# va108xx register map
Vendor: VORAGO TECHNOLOGIES; Series: M0; File version: 1.2-IAR
ARM 32-bit Cortex-M0 Microcontroller based device, CPU clock up to 50MHz
CPU: CM0 r0p0, little endian, no MPU, no FPU, 2 interrupt priority bits
Registers are 32-bit, read-write, reset 0x0 unless marked. A register's access mark holds for its fields unless they carry their own. Offsets are from the block's base; lines under a group give offsets from that group; [hi:lo] are bit positions; {n}, {i} and the like mark numbered series; 'fields as' and 'values as' point back to an identical list; <NAME> marks a mode.

## Memory map
0x40000000 SYSCONFIG size 0x1000 — System Configuration Peripheral
0x40001000 IRQSEL size 0x1000 — Interrupt Selector Peripheral
0x40002000 IOCONFIG size 0x1000 — IO Pin Configuration Peripheral
0x40003000 UTILITY size 0x1000 — Utility Peripheral
0x40020000 TIM0 size 0x1000 — Timer/Counter Peripheral
{0x40020000+0x1000*n} TIM{n} size 0x1000 (n=1..23)
0x40040000 UARTA size 0x1000 — UART Peripheral
0x40041000 UARTB size 0x1000
0x40050000 SPIA size 0x1000 — SPI Peripheral
0x40051000 SPIB size 0x1000
0x40052000 SPIC size 0x1000
0x40060000 I2CA size 0x1000 — I2C Peripheral
0x40061000 I2CB size 0x1000
0x50000000 PORTA size 0x1000 — GPIO Peripheral
0x50001000 PORTB size 0x1000

## Interrupts
{n} OC{n} (IRQSEL) (n=0..31)

## SYSCONFIG — System Configuration Peripheral
Base 0x40000000
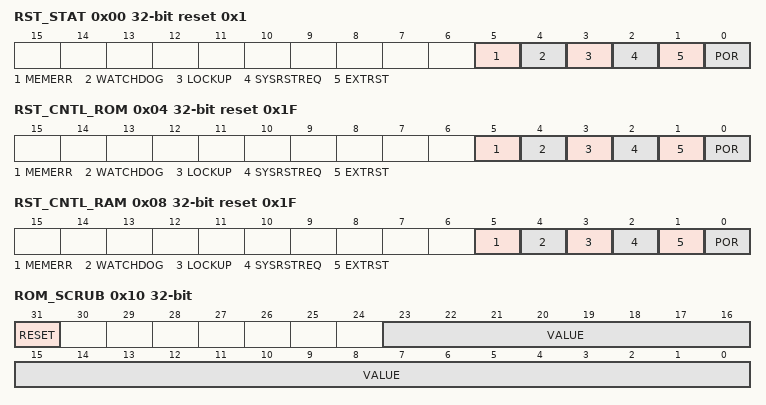
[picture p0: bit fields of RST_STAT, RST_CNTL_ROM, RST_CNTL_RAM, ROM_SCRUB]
0x00 RST_STAT reset 0x1 — System Reset Status
  [5] MEMERR — Memory Error Reset Status
  [4] WATCHDOG — WATCHDOG Reset Status
  [3] LOCKUP — LOCKUP Reset Status
  [2] SYSRSTREQ — SYSRESETREQ Reset Status
  [1] EXTRST — External Reset Status
  [0] POR — Power On Reset Status
0x04 RST_CNTL_ROM reset 0x1F — ROM Reset Control
  fields as RST_STAT
0x08 RST_CNTL_RAM reset 0x1F — RAM Reset Control
  fields as RST_STAT
0x0C ROM_PROT reset 0x1 — ROM Protection Configuration
  [0] WREN — ROM Write Enable Bit
0x10 ROM_SCRUB — ROM Scrub Period Configuration
  [31] RESET wo write-1-clears — Reset Counter
  [23:0] VALUE — Counter divide value
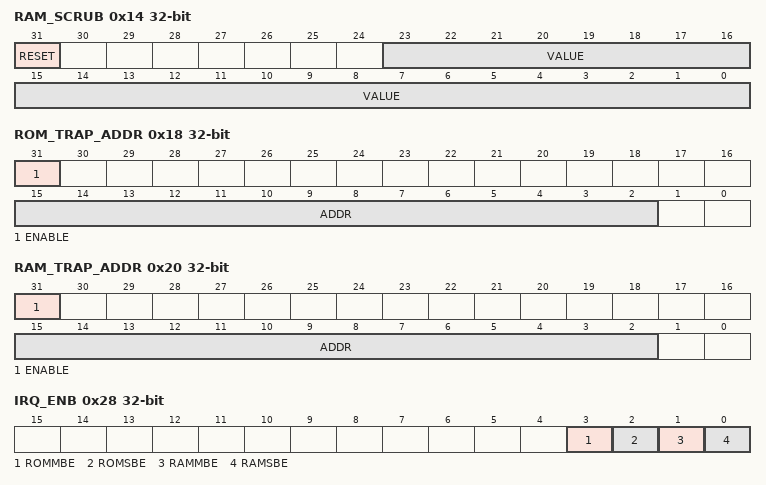
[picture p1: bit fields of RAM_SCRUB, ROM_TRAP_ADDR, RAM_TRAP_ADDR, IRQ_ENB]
0x14 RAM_SCRUB — RAM Scrub Period Configuration
  fields as ROM_SCRUB
0x18 ROM_TRAP_ADDR — ROM Trap Address
  [31] ENABLE — Trap Enable Bit
  [15:2] ADDR — Trap Address Match Bits
0x1C ROM_TRAP_SYND — ROM Trap Syndrome
  [19:0] SYND — Trap Syndrom Bits
0x20 RAM_TRAP_ADDR — RAM Trap Address
  fields as ROM_TRAP_ADDR
0x24 RAM_TRAP_SYND — RAM Trap Syndrome
  [19:0] SYND — Trap Syndrom Bits
0x28 IRQ_ENB — Enable EDAC Error Interrupt Register
  [3] ROMMBE — ROM Multi Bit Interrupt
  [2] ROMSBE — ROM Single Bit Interrupt
  [1] RAMMBE — RAM Multi Bit Interrupt
  [0] RAMSBE — RAM Single Bit Interrupt
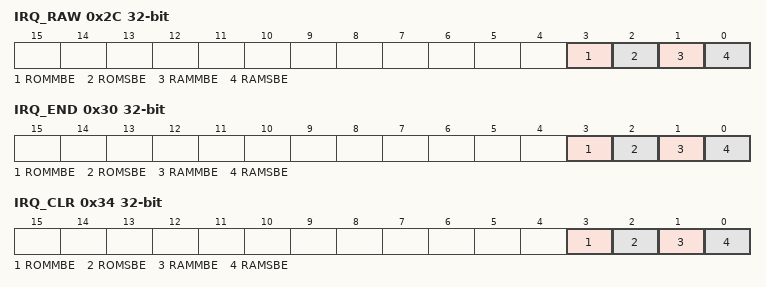
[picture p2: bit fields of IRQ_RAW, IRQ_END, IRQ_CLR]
0x2C IRQ_RAW ro — Raw EDAC Error Interrupt Status
  fields as IRQ_ENB
0x30 IRQ_END ro — Enabled EDAC Error Interrupt Status
  fields as IRQ_ENB
0x34 IRQ_CLR wo write-1-clears — Clear EDAC Error Interrupt Status
  fields as IRQ_ENB
0x38 RAM_SBE — Count of RAM EDAC Single Bit Errors
0x3C RAM_MBE — Count of RAM EDAC Multi Bit Errors
0x40 ROM_SBE — Count of ROM EDAC Single Bit Errors
0x44 ROM_MBE — Count of ROM EDAC Multi Bit Errors
0x48 IOCONFIG_CLKDIV0 ro — IO Configuration Clock Divider Register
{0x48+4i} IOCONFIG_CLKDIV{i} (i=1..7) — IO Configuration Clock Divider Register
0x68 ROM_RETRIES ro — ROM BOOT Retry count
0x6C REFRESH_CONFIG — Register Refresh Control
0x70 TIM_RESET reset 0xFFFFFFFF — TIM Reset Control
0x74 TIM_CLK_ENABLE — TIM Enable Control
0x78 PERIPHERAL_RESET reset 0xFFFFFFFF — Peripheral Reset Control
0x7C PERIPHERAL_CLK_ENABLE — Peripheral Enable Control
0x80 LOCKUP_RESET reset 0x1 — Lockup Reset Configuration
  [0] LREN — Lockup Reset Enable Bit
0xFF0 EF_CONFIG ro — EFuse Config Register
0xFF4 EF_ID ro — EFuse ID Register
0xFF8 PROCID ro reset 0x40017E3 — Processor ID Register
0xFFC PERID ro reset 0x8007E1 — Peripheral ID Register

## Licence text in the file
VORAGO Technologies ---------------------------------------------------------------------------- Copyright (c) 2013-2016 VORAGO Technologies . BY DOWNLOADING, INSTALLING OR USING THIS SOFTWARE, YOU AGREE TO BE BOUND BY ALL THE TERMS. AND CONDITIONS OF THE VORAGO TECHNOLOGIES END USER LICENSE AGREEMENT. . THIS SOFTWARE IS PROVIDED "AS IS". NO WARRANTIES, WHETHER EXPRESS, IMPLIED. OR STATUTORY, INCLUDING, BUT NOT LIMITED TO, IMPLIED WARRANTIES OF. MERCHANTABILITY AND FITNESS FOR A PARTICULAR PURPOSE APPLY TO THIS SOFTWARE. VORAGO TECHNOLOGIES SHALL NOT, IN ANY CIRCUMSTANCES, BE LIABLE. FOR SPECIAL, INCIDENTAL, OR CONSEQUENTIAL DAMAGES, FOR ANY REASON WHATSOEVER.
